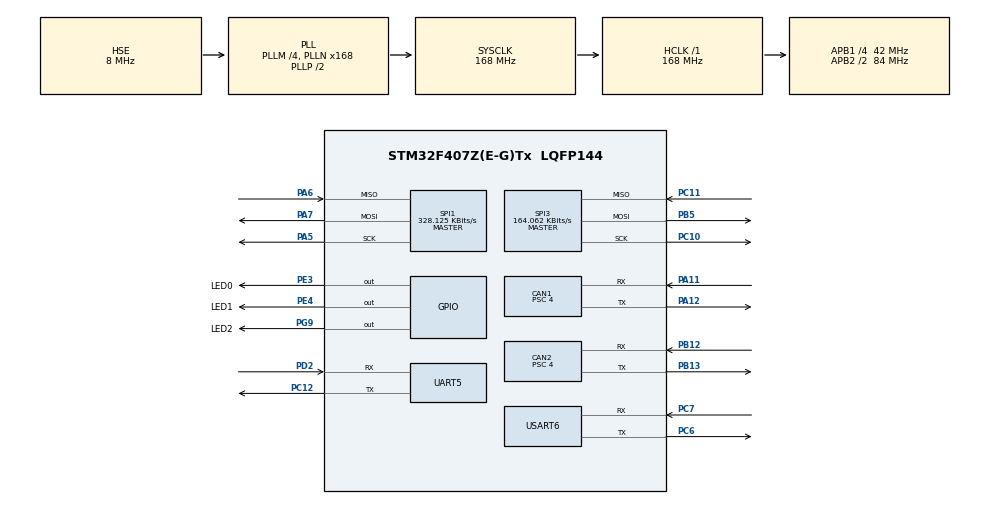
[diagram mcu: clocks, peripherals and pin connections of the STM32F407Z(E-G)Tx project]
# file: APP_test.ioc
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CAN1.ABOM=ENABLE
CAN1.BS1=CAN_BS1_13TQ
CAN1.BS2=CAN_BS2_2TQ
CAN1.CalculateBaudRate=656250
CAN1.CalculateTimeBit=1523
CAN1.CalculateTimeQuantum=95.23809523809524
CAN1.Mode=CAN_MODE_LOOPBACK
CAN1.NART=ENABLE
CAN1.Prescaler=4
CAN2.ABOM=ENABLE
CAN2.BS1=CAN_BS1_13TQ
CAN2.BS2=CAN_BS2_2TQ
CAN2.CalculateBaudRate=656250
CAN2.CalculateTimeBit=1523
CAN2.CalculateTimeQuantum=95.23809523809524
CAN2.Mode=CAN_MODE_LOOPBACK
CAN2.NART=ENABLE
CAN2.Prescaler=4
Mcu.Family=STM32F4
Mcu.Name=STM32F407Z(E-G)Tx
Mcu.Package=LQFP144
NVIC.CAN1_RX0_IRQn=true\:0\:0\:false\:false\:true\:false\:true\:true\:true
NVIC.CAN2_RX0_IRQn=true\:0\:0\:false\:false\:true\:false\:true\:true\:true
NVIC.PriorityGroup=NVIC_PRIORITYGROUP_4
NVIC.TIM7_IRQn=true\:15\:0\:false\:false\:true\:false\:false\:true\:true
NVIC.TimeBase=TIM7_IRQn
NVIC.TimeBaseIP=TIM7
NVIC.UART5_IRQn=true\:0\:0\:false\:false\:true\:false\:true\:true\:true
NVIC.USART6_IRQn=true\:0\:0\:false\:false\:true\:false\:true\:true\:true
PA11.Mode=CAN_Activate
PA11.Signal=CAN1_RX
PA12.Mode=CAN_Activate
PA12.Signal=CAN1_TX
PA5.Mode=Full_Duplex_Master
PA5.Signal=SPI1_SCK
PA6.Mode=Full_Duplex_Master
PA6.Signal=SPI1_MISO
PA7.Mode=Full_Duplex_Master
PA7.Signal=SPI1_MOSI
PB12.Mode=CAN_Activate
PB12.Signal=CAN2_RX
PB13.Mode=CAN_Activate
PB13.Signal=CAN2_TX
PB5.Mode=Full_Duplex_Master
PB5.Signal=SPI3_MOSI
PC10.Mode=Full_Duplex_Master
PC10.Signal=SPI3_SCK
PC11.Mode=Full_Duplex_Master
PC11.Signal=SPI3_MISO
PC12.Mode=Asynchronous
PC12.Signal=UART5_TX
PC14-OSC32_IN.Mode=LSE-External-Oscillator
PC14-OSC32_IN.Signal=RCC_OSC32_IN
PC15-OSC32_OUT.Mode=LSE-External-Oscillator
PC15-OSC32_OUT.Signal=RCC_OSC32_OUT
PC6.Mode=Asynchronous
PC6.Signal=USART6_TX
PC7.Mode=Asynchronous
PC7.Signal=USART6_RX
PD2.Mode=Asynchronous
PD2.Signal=UART5_RX
PE3.GPIO_Label=LED0
PE3.Signal=GPIO_Output
PE4.GPIO_Label=LED1
PE4.Signal=GPIO_Output
PG9.GPIO_Label=LED2
PG9.Signal=GPIO_Output
PH0-OSC_IN.Mode=HSE-External-Oscillator
PH0-OSC_IN.Signal=RCC_OSC_IN
PH1-OSC_OUT.Mode=HSE-External-Oscillator
PH1-OSC_OUT.Signal=RCC_OSC_OUT
ProjectManager.HeapSize=0x200
ProjectManager.StackSize=0x400
ProjectManager.TargetToolchain=CMake
RCC.48MHZClocksFreq_Value=84000000
RCC.AHBFreq_Value=168000000
RCC.APB1CLKDivider=RCC_HCLK_DIV4
RCC.APB1Freq_Value=42000000
RCC.APB1TimFreq_Value=84000000
RCC.APB2CLKDivider=RCC_HCLK_DIV2
RCC.APB2Freq_Value=84000000
RCC.APB2TimFreq_Value=168000000
RCC.CortexFreq_Value=168000000
RCC.HCLKFreq_Value=168000000
RCC.HSE_VALUE=8000000
RCC.HSI_VALUE=16000000
RCC.PLLM=4
RCC.PLLN=168
RCC.PLLSourceVirtual=RCC_PLLSOURCE_HSE
RCC.SYSCLKFreq_VALUE=168000000
RCC.SYSCLKSource=RCC_SYSCLKSOURCE_PLLCLK
RCC.VCOOutputFreq_Value=336000000
RealThread.RT-Thread.3.1.3.RTAaThreadCcRTOSJjkernel=true
RealThread.RT-Thread.3.1.3.RTAaThreadCcRTOSJjshell=true
RealThread.RT-Thread.3.1.3.RT_DEBUG=1
RealThread.RT-Thread.3.1.3.RT_DEBUG_INIT=1
RealThread.RT-Thread.3.1.3.RT_USING_EVENT=1
RealThread.RT-Thread.3.1.3.RT_USING_HEAP=1
RealThread.RT-Thread.3.1.3.RT_USING_HOOK=1
RealThread.RT-Thread.3.1.3.RT_USING_IDLE_HOOK=1
RealThread.RT-Thread.3.1.3.RT_USING_MAILBOX=1
RealThread.RT-Thread.3.1.3.RT_USING_MESSAGEQUEUE=1
RealThread.RT-Thread.3.1.3.RT_USING_MUTEX=1
RealThread.RT-Thread.3.1.3.RT_USING_OVERFLOW_CHECK=1
RealThread.RT-Thread.3.1.3.RT_USING_TINY_SIZE=1
SPI1.BaudRatePrescaler=SPI_BAUDRATEPRESCALER_256
SPI1.CLKPhase=SPI_PHASE_2EDGE
SPI1.CLKPolarity=SPI_POLARITY_HIGH
SPI1.CalculateBaudRate=328.125 KBits/s
SPI1.Direction=SPI_DIRECTION_2LINES
SPI1.Mode=SPI_MODE_MASTER
SPI1.VirtualType=VM_MASTER
SPI3.BaudRatePrescaler=SPI_BAUDRATEPRESCALER_256
SPI3.CLKPhase=SPI_PHASE_2EDGE
SPI3.CLKPolarity=SPI_POLARITY_HIGH
SPI3.CalculateBaudRate=164.062 KBits/s
SPI3.Direction=SPI_DIRECTION_2LINES
SPI3.Mode=SPI_MODE_MASTER
SPI3.VirtualType=VM_MASTER
UART5.VirtualMode=Asynchronous
USART6.VirtualMode=VM_ASYNC
VP_RealThread.RT-Thread_VS_RTOSJjRTAaThread_3.1.3.Mode=RTOSJjRTAaThread
VP_SYS_VS_tim7.Mode=TIM7
board=custom

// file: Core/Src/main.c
/* USER CODE BEGIN Header */
/**
  ******************************************************************************
  * @file           : main.c
  * @brief          : Main program body
  ******************************************************************************
  * @attention
  *
  * Copyright (c) 2026 STMicroelectronics.
  * All rights reserved.
  *
  * This software is licensed under terms that can be found in the LICENSE file
  * in the root directory of this software component.
  * If no LICENSE file comes with this software, it is provided AS-IS.
  *
  ******************************************************************************
  */
/* USER CODE END Header */
#include "main.h"
#include "can.h"
#include "spi.h"
#include "usart.h"
#include "gpio.h"

/* USER CODE BEGIN Includes */
#include <rtthread.h>
/* USER CODE END Includes */

void SystemClock_Config(void);
/* USER CODE BEGIN PFP */
void bms_app_start(void);   /* bms_app.c: 启动 BMS 线程所需的 CAN/遥测初始化 */
/* USER CODE END PFP */

int main(void)
{

  /* MCU Configuration--------------------------------------------------------*/

  /* Reset of all peripherals, Initializes the Flash interface and the Systick. */
  HAL_Init();

  /* Configure the system clock */
  SystemClock_Config();

  /* USER CODE BEGIN SysInit */
  /* rt_hw_board_init() 在 PLL 启动前按 HSI 频率装了 SysTick LOAD；现在时钟
   * 已升到目标频率，按实际 SystemCoreClock 重装，否则 RT tick 会按倍率偏快，
   * 所有 rt_thread_mdelay 都缩水。SysTick 是 RTOS 时基，TIM7(HAL tick)不受影响。 */
  SysTick->LOAD = (uint32_t)(SystemCoreClock / RT_TICK_PER_SECOND) - 1UL;
  SysTick->VAL  = 0UL;
  SysTick->CTRL |= SysTick_CTRL_ENABLE_Msk;
  /* USER CODE END SysInit */

  /* Initialize all configured peripherals */
  MX_GPIO_Init();
  MX_UART5_Init();
  MX_USART6_UART_Init();
  MX_CAN1_Init();
  MX_CAN2_Init();
  MX_SPI1_Init();
  MX_SPI3_Init();
  /* USER CODE BEGIN 2 */
  /* 启动 BMS 应用：CAN 过滤器/缓冲、状态机、双口遥测(含 0x13 重入) */
  bms_app_start();
  /* USER CODE END 2 */

  /* Infinite loop */
  while (1)
  {

    /* USER CODE BEGIN 3 */
    /* 让出 CPU：main 优先级(10)高于 LED 线程(15)，忙等会饿死 LED 线程 */
    rt_thread_mdelay(1000);
  }
  /* USER CODE END 3 */
}

void SystemClock_Config(void)
{
  RCC_OscInitTypeDef RCC_OscInitStruct = {0};
  RCC_ClkInitTypeDef RCC_ClkInitStruct = {0};

  /** Configure the main internal regulator output voltage
  */
  __HAL_RCC_PWR_CLK_ENABLE();
  __HAL_PWR_VOLTAGESCALING_CONFIG(PWR_REGULATOR_VOLTAGE_SCALE1);

  /** Initializes the RCC Oscillators according to the specified parameters
  * in the RCC_OscInitTypeDef structure.
  */
  RCC_OscInitStruct.OscillatorType = RCC_OSCILLATORTYPE_HSE;
  RCC_OscInitStruct.HSEState = RCC_HSE_ON;
  RCC_OscInitStruct.PLL.PLLState = RCC_PLL_ON;
  RCC_OscInitStruct.PLL.PLLSource = RCC_PLLSOURCE_HSE;
  RCC_OscInitStruct.PLL.PLLM = 4;
  RCC_OscInitStruct.PLL.PLLN = 168;
  RCC_OscInitStruct.PLL.PLLP = RCC_PLLP_DIV2;
  RCC_OscInitStruct.PLL.PLLQ = 4;
  if (HAL_RCC_OscConfig(&RCC_OscInitStruct) != HAL_OK)
  {
    Error_Handler();
  }

  /** Initializes the CPU, AHB and APB buses clocks
  */
  RCC_ClkInitStruct.ClockType = RCC_CLOCKTYPE_HCLK|RCC_CLOCKTYPE_SYSCLK
                              |RCC_CLOCKTYPE_PCLK1|RCC_CLOCKTYPE_PCLK2;
  RCC_ClkInitStruct.SYSCLKSource = RCC_SYSCLKSOURCE_PLLCLK;
  RCC_ClkInitStruct.AHBCLKDivider = RCC_SYSCLK_DIV1;
  RCC_ClkInitStruct.APB1CLKDivider = RCC_HCLK_DIV4;
  RCC_ClkInitStruct.APB2CLKDivider = RCC_HCLK_DIV2;

  if (HAL_RCC_ClockConfig(&RCC_ClkInitStruct, FLASH_LATENCY_5) != HAL_OK)
  {
    Error_Handler();
  }
}

void HAL_TIM_PeriodElapsedCallback(TIM_HandleTypeDef *htim)
{
  if (htim->Instance == TIM7)
  {
    HAL_IncTick();
  }
}

void Error_Handler(void)
{
  __disable_irq();
  while (1)
  {
  }
}
